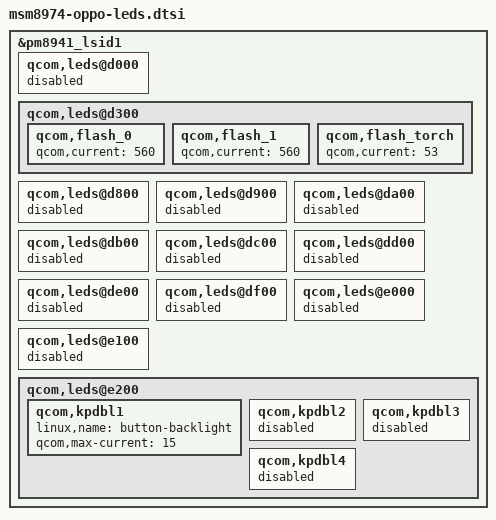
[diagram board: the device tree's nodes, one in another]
/* Copyright (c) 2012-2013, The Linux Foundation. All rights reserved.
 *
 * This program is free software; you can redistribute it and/or modify
 * it under the terms of the GNU General Public License version 2 and
 * only version 2 as published by the Free Software Foundation.
 *
 * This program is distributed in the hope that it will be useful,
 * but WITHOUT ANY WARRANTY; without even the implied warranty of
 * MERCHANTABILITY or FITNESS FOR A PARTICULAR PURPOSE.  See the
 * GNU General Public License for more details.
 */

/include/ "../msm8974-leds.dtsi"

&pm8941_lsid1 {
	qcom,leds@d000 {
		status = "disabled";
	};

	qcom,leds@d300 {
		qcom,flash_0 {
			qcom,current = <560>;
		};

		qcom,flash_1 {
			qcom,current = <560>;
		};

		qcom,flash_torch {
			qcom,current = <53>;
		};
	};

	qcom,leds@d800 {
		status = "disabled";
	};

	qcom,leds@d900 {
		status = "disabled";
	};

	qcom,leds@da00 {
		status = "disabled";
	};

	qcom,leds@db00 {
		status = "disabled";
	};

	qcom,leds@dc00 {
		status = "disabled";
	};

	qcom,leds@dd00 {
		status = "disabled";
	};

	qcom,leds@de00 {
		status = "disabled";
	};

	qcom,leds@df00 {
		status = "disabled";
	};

	qcom,leds@e000 {
		status = "disabled";
	};

	qcom,leds@e100 {
		status = "disabled";
	};

	qcom,leds@e200 {
		qcom,kpdbl1 {
			linux,name = "button-backlight";
			qcom,max-current = <15>;
		};

		qcom,kpdbl2 {
			status = "disabled";
		};

		qcom,kpdbl3 {
			status = "disabled";
		};

		qcom,kpdbl4 {
			status = "disabled";
		};
	};
};
